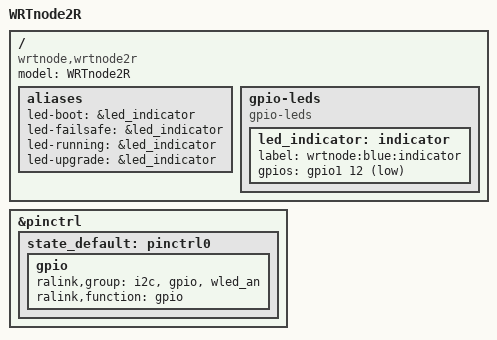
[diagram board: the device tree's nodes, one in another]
/dts-v1/;

#include "WRTNODE2.dtsi"

/ {
	compatible = "wrtnode,wrtnode2r", "wrtnode,wrtnode2", "mediatek,mt7628an-soc";
	model = "WRTnode2R";

	aliases {
		led-boot = &led_indicator;
		led-failsafe = &led_indicator;
		led-running = &led_indicator;
		led-upgrade = &led_indicator;
	};

	gpio-leds {
		compatible = "gpio-leds";

		led_indicator: indicator {
			label = "wrtnode:blue:indicator";
			gpios = <&gpio1 12 GPIO_ACTIVE_LOW>;
		};
	};
};

&pinctrl {
	state_default: pinctrl0 {
		gpio {
			ralink,group = "i2c", "gpio", "wled_an";
			ralink,function = "gpio";
		};
	};
};
